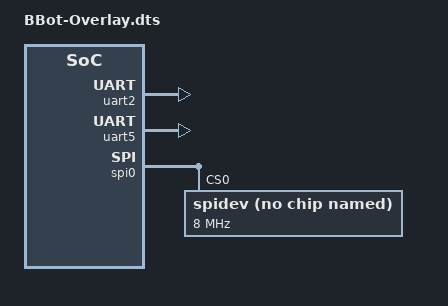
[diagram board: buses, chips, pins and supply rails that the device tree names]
/*
 * Copyright (C) 2013 CircuitCo
 *
 * Virtual cape for UART1 on connector pins P9.24 P9.26
 *
 * This program is free software; you can redistribute it and/or modify
 * it under the terms of the GNU General Public License version 2 as
 * published by the Free Software Foundation.
 */
/dts-v1/;
/plugin/;

/ {
	compatible = "ti,beaglebone", "ti,beaglebone-black";

	/* identification */
	part-number = "BBot-Overlay";
	version = "00A0";

	/* state the resources this cape uses */
	exclusive-use =
		/* the pin header uses */
		"P9.24",	/* uart1_txd */
		"P9.26",	/* uart1_rxd */
		"P9.13",	/* uart4_txd */
		"P9.11",	/* uart4_rxd */
		"P8.7",		/* GPIO */
		"P8.9",		/* GPIO */
		"P8.11",	/* GPIO */
		"P9.17",	/*SPI_0_CS*/
		"P9.18",	/*SPI_0_D1*/
		"P9.21",	/*SPI_0_D0*/
		"P9.22",	/*SPI_0_SCK*/
		
		/* the hardware ip uses */
		"uart1",
		"uart4",
		"spi0";

	/*Set the UART0 Pin mux and three GPIOs we're using*/
	fragment@0 {
		target = <&am33xx_pinmux>;
		__overlay__ {
			bb_uart1_pins: pinmux_bb_uart1_pins {
				pinctrl-single,pins = <
				
					0x184 0x20 		/* P9.24 uart1_txd  OUTPUT MuxMode = 0 	*/
					0x180 0x20 		/* P9.26 uart1_rxd  INPUT  MuxMode = 0	*/
					
					0x090 0x0f 		/*P8_07 output mode 7 (gpio) pull disabled - UART Mux To FPGA 0*/
					0x09C 0x0f      /*P8_09 output mode 7 (gpio) pull disabled - UART Mux To FPGA 1*/
					0x034 0x0f      /*P8_11 output mode 7 (gpio) pull disabled - UART Mux To FPGA 2*/
				>;
			};
			
			/*Set Pin Mux For Uart4 Pins*/
			bb_uart4_pins: pinmux_bb_uart4_pins {
				pinctrl-single,pins = <
					0x070 0x26	/* gpmc_wait0.uart4_rxd | MODE6 */
					0x074 0x06	/* gpmc_wpn.uart4_txd | MODE6 */
				>;
			};
			
			/*Set Pin Mux For SPI0 Pins*/
			spi0_pins_s0: pinmux_spi0_pins_s0 {
                pinctrl-single,pins = <
                  0x150 0x30 /* spi0_sclk, INPUT_PULLUP | MODE0 */
                  0x154 0x30 /* spi0_d0, INPUT_PULLUP | MODE0 */
                  0x158 0x10 /* spi0_d1, OUTPUT_PULLUP | MODE0 */
                  0x15C 0x10 /* spi0_cs0, OUTPUT_PULLUP | MODE0 */
                >;
            };
			
		};
	};

	/*Target UAR1 hardware with the pinmux*/
	fragment@1 {
		target = <&uart2>;	/* really uart1 */
		__overlay__ {
			status = "okay";
			pinctrl-names = "default";
			pinctrl-0 = <&bb_uart1_pins>;
		};
	};
	


	/*Target Uart4 Hardware with the muxed pins*/
	fragment@2 {
		target = <&uart5>;	/* really uart4 - numbering is off by 1 */
		__overlay__ {
			status = "okay";
			pinctrl-names = "default";
			pinctrl-0 = <&bb_uart4_pins>;
		};
	};

	/*Target the SPI0 Hardware with the muxed pins*/
	fragment@3 {
        target = <&spi0>;
        __overlay__ {
             #address-cells = <1>;
             #size-cells = <0>;
 
             status = "okay";
             pinctrl-names = "default";
             pinctrl-0 = <&spi0_pins_s0>;
              
              /*define a spi device - appears in /dev as spidev1.0*/
             spidev@0 {
                 spi-max-frequency = <8000000>;
                 reg = <0>;
                 compatible = "spidev";
             };
             
             /* Use this for a second chip select
             it will show up in /dev as spidev1.1
             spidev@1 {
                 spi-max-frequency = <8000000>;
                 reg = <1>;
                 compatible = "spidev";
             };
             */
        };
	};
};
